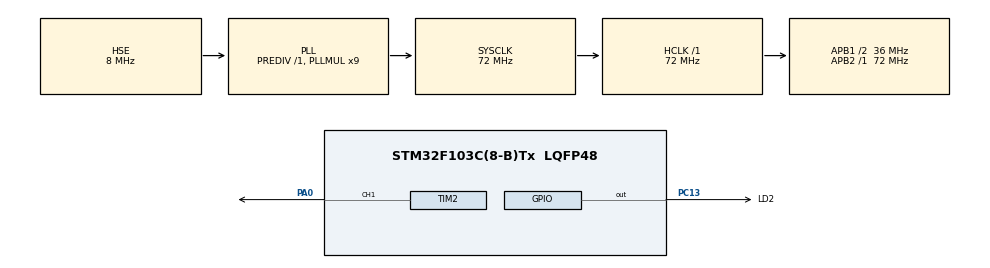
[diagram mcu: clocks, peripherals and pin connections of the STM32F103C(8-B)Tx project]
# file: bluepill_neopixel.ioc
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Dma.Request0=TIM2_CH1
Dma.TIM2_CH1.0.Direction=DMA_MEMORY_TO_PERIPH
Dma.TIM2_CH1.0.Instance=DMA1_Channel5
Dma.TIM2_CH1.0.MemDataAlignment=DMA_MDATAALIGN_HALFWORD
Dma.TIM2_CH1.0.MemInc=DMA_MINC_ENABLE
Dma.TIM2_CH1.0.Mode=DMA_NORMAL
Dma.TIM2_CH1.0.PeriphDataAlignment=DMA_PDATAALIGN_HALFWORD
Dma.TIM2_CH1.0.PeriphInc=DMA_PINC_DISABLE
Dma.TIM2_CH1.0.Priority=DMA_PRIORITY_LOW
Mcu.Family=STM32F1
Mcu.Name=STM32F103C(8-B)Tx
Mcu.Package=LQFP48
NVIC.DMA1_Channel5_IRQn=true\:0\:0\:false\:false\:true\:false\:true\:true
NVIC.PriorityGroup=NVIC_PRIORITYGROUP_4
NVIC.TIM2_IRQn=true\:0\:0\:false\:false\:true\:true\:true\:true
PA0-WKUP.Signal=S_TIM2_CH1_ETR
PA13.Mode=Serial_Wire
PA13.Signal=SYS_JTMS-SWDIO
PA14.Mode=Serial_Wire
PA14.Signal=SYS_JTCK-SWCLK
PC13-TAMPER-RTC.GPIO_Label=LD2
PC13-TAMPER-RTC.GPIO_ModeDefaultOutputPP=GPIO_MODE_OUTPUT_OD
PC13-TAMPER-RTC.GPIO_PuPd=GPIO_PULLUP
PC13-TAMPER-RTC.Signal=GPIO_Output
PC14-OSC32_IN.Mode=LSE-External-Oscillator
PC14-OSC32_IN.Signal=RCC_OSC32_IN
PC15-OSC32_OUT.Mode=LSE-External-Oscillator
PC15-OSC32_OUT.Signal=RCC_OSC32_OUT
PD0-OSC_IN.Mode=HSE-External-Oscillator
PD0-OSC_IN.Signal=RCC_OSC_IN
PD1-OSC_OUT.Mode=HSE-External-Oscillator
PD1-OSC_OUT.Signal=RCC_OSC_OUT
ProjectManager.HeapSize=0x200
ProjectManager.StackSize=0x400
ProjectManager.TargetToolchain=STM32CubeIDE
RCC.AHBFreq_Value=72000000
RCC.APB1CLKDivider=RCC_HCLK_DIV2
RCC.APB1Freq_Value=36000000
RCC.APB1TimFreq_Value=72000000
RCC.APB2Freq_Value=72000000
RCC.APB2TimFreq_Value=72000000
RCC.HCLKFreq_Value=72000000
RCC.PLLMUL=RCC_PLL_MUL9
RCC.PLLSourceVirtual=RCC_PLLSOURCE_HSE
RCC.SYSCLKFreq_VALUE=72000000
RCC.SYSCLKSource=RCC_SYSCLKSOURCE_PLLCLK
RCC.USBFreq_Value=72000000
SH.S_TIM2_CH1_ETR.0=TIM2_CH1,PWM Generation1 CH1
TIM2.Channel-PWM\ Generation1\ CH1=TIM_CHANNEL_1
TIM2.Period=90-1
VP_TIM2_VS_ClockSourceINT.Mode=Internal
board=custom

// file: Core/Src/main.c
/* USER CODE BEGIN Header */
/**
  ******************************************************************************
  * @file           : main.c
  * @brief          : Main program body
  ******************************************************************************
  * @attention
  *
  * Copyright (c) 2024 STMicroelectronics.
  * All rights reserved.
  *
  * This software is licensed under terms that can be found in the LICENSE file
  * in the root directory of this software component.
  * If no LICENSE file comes with this software, it is provided AS-IS.
  *
  ******************************************************************************
  */
/* USER CODE END Header */
#include "main.h"

/* USER CODE BEGIN Includes */
#include "ws2812.h"
/* USER CODE END Includes */

/* USER CODE BEGIN PD */
#define NEOPIXEL_NUM 16
#define NEOPIXEL_BUF_SIZE NEOPIXEL_NUM * WS2812_MSG_LENGTH + 2
#define NPX_TIM_FREQ_HZ 72e6 /* Each clock tick on timer 1 takes around 11.904 nanoseconds */
#define NPX_TIM_CHANNEL TIM_CHANNEL_1
#define NPX_HTIM htim2

/* USER CODE END PD */

TIM_HandleTypeDef htim2;
DMA_HandleTypeDef hdma_tim2_ch1;

void SystemClock_Config(void);
static void MX_GPIO_Init(void);
static void MX_DMA_Init(void);
static void MX_TIM2_Init(void);
void full_led_pulse(WS2812_RGBTypeDef color);
void circular_rainbow(double rotation_time, int rotations);
void circular_rainbow_v2(double rotation_time, int rotations);
void full_led_pulse_hsv(WS2812_HSVTypeDef color);
void soft_start_hsv(WS2812_HSVTypeDef color);

/* USER CODE BEGIN 0 */
WS2812_HandleTypeDef neopixel;
int neopixel_dma_buf_size = NEOPIXEL_BUF_SIZE;
uint16_t neopixel_dma_buf[NEOPIXEL_BUF_SIZE] = {0};

/* USER CODE END 0 */

int main(void)
{

  /* MCU Configuration--------------------------------------------------------*/

  /* Reset of all peripherals, Initializes the Flash interface and the Systick. */
  HAL_Init();

  /* Configure the system clock */
  SystemClock_Config();

  /* Initialize all configured peripherals */
  MX_GPIO_Init();
  MX_DMA_Init();
  MX_TIM2_Init();
  /* USER CODE BEGIN 2 */
  ws2812_init(&neopixel, &NPX_HTIM, NPX_TIM_CHANNEL, NPX_TIM_FREQ_HZ, neopixel_dma_buf, NEOPIXEL_BUF_SIZE, NEOPIXEL_NUM);

  WS2812_HSVTypeDef color = {300.0,1.0,0.15};
  ws2812_reset(&neopixel);

  circular_rainbow(5,1);
  HAL_Delay(2000);

  soft_start_hsv(color);
  /* USER CODE END 2 */

  /* Infinite loop */
  while (1)
  {

  }
}

void SystemClock_Config(void)
{
  RCC_OscInitTypeDef RCC_OscInitStruct = {0};
  RCC_ClkInitTypeDef RCC_ClkInitStruct = {0};

  /** Initializes the RCC Oscillators according to the specified parameters
  * in the RCC_OscInitTypeDef structure.
  */
  RCC_OscInitStruct.OscillatorType = RCC_OSCILLATORTYPE_HSE;
  RCC_OscInitStruct.HSEState = RCC_HSE_ON;
  RCC_OscInitStruct.HSEPredivValue = RCC_HSE_PREDIV_DIV1;
  RCC_OscInitStruct.HSIState = RCC_HSI_ON;
  RCC_OscInitStruct.PLL.PLLState = RCC_PLL_ON;
  RCC_OscInitStruct.PLL.PLLSource = RCC_PLLSOURCE_HSE;
  RCC_OscInitStruct.PLL.PLLMUL = RCC_PLL_MUL9;
  if (HAL_RCC_OscConfig(&RCC_OscInitStruct) != HAL_OK)
  {
    Error_Handler();
  }

  /** Initializes the CPU, AHB and APB buses clocks
  */
  RCC_ClkInitStruct.ClockType = RCC_CLOCKTYPE_HCLK|RCC_CLOCKTYPE_SYSCLK
                              |RCC_CLOCKTYPE_PCLK1|RCC_CLOCKTYPE_PCLK2;
  RCC_ClkInitStruct.SYSCLKSource = RCC_SYSCLKSOURCE_PLLCLK;
  RCC_ClkInitStruct.AHBCLKDivider = RCC_SYSCLK_DIV1;
  RCC_ClkInitStruct.APB1CLKDivider = RCC_HCLK_DIV2;
  RCC_ClkInitStruct.APB2CLKDivider = RCC_HCLK_DIV1;

  if (HAL_RCC_ClockConfig(&RCC_ClkInitStruct, FLASH_LATENCY_2) != HAL_OK)
  {
    Error_Handler();
  }
}

static void MX_TIM2_Init(void)
{

  TIM_ClockConfigTypeDef sClockSourceConfig = {0};
  TIM_MasterConfigTypeDef sMasterConfig = {0};
  TIM_OC_InitTypeDef sConfigOC = {0};

  htim2.Instance = TIM2;
  htim2.Init.Prescaler = 0;
  htim2.Init.CounterMode = TIM_COUNTERMODE_UP;
  htim2.Init.Period = 90-1;
  htim2.Init.ClockDivision = TIM_CLOCKDIVISION_DIV1;
  htim2.Init.AutoReloadPreload = TIM_AUTORELOAD_PRELOAD_DISABLE;
  if (HAL_TIM_Base_Init(&htim2) != HAL_OK)
  {
    Error_Handler();
  }
  sClockSourceConfig.ClockSource = TIM_CLOCKSOURCE_INTERNAL;
  if (HAL_TIM_ConfigClockSource(&htim2, &sClockSourceConfig) != HAL_OK)
  {
    Error_Handler();
  }
  if (HAL_TIM_PWM_Init(&htim2) != HAL_OK)
  {
    Error_Handler();
  }
  sMasterConfig.MasterOutputTrigger = TIM_TRGO_RESET;
  sMasterConfig.MasterSlaveMode = TIM_MASTERSLAVEMODE_DISABLE;
  if (HAL_TIMEx_MasterConfigSynchronization(&htim2, &sMasterConfig) != HAL_OK)
  {
    Error_Handler();
  }
  sConfigOC.OCMode = TIM_OCMODE_PWM1;
  sConfigOC.Pulse = 0;
  sConfigOC.OCPolarity = TIM_OCPOLARITY_HIGH;
  sConfigOC.OCFastMode = TIM_OCFAST_DISABLE;
  if (HAL_TIM_PWM_ConfigChannel(&htim2, &sConfigOC, TIM_CHANNEL_1) != HAL_OK)
  {
    Error_Handler();
  }
  HAL_TIM_MspPostInit(&htim2);

}

static void MX_DMA_Init(void)
{

  /* DMA controller clock enable */
  __HAL_RCC_DMA1_CLK_ENABLE();

  /* DMA interrupt init */
  /* DMA1_Channel5_IRQn interrupt configuration */
  HAL_NVIC_SetPriority(DMA1_Channel5_IRQn, 0, 0);
  HAL_NVIC_EnableIRQ(DMA1_Channel5_IRQn);

}

static void MX_GPIO_Init(void)
{
  GPIO_InitTypeDef GPIO_InitStruct = {0};

  /* GPIO Ports Clock Enable */
  __HAL_RCC_GPIOC_CLK_ENABLE();
  __HAL_RCC_GPIOD_CLK_ENABLE();
  __HAL_RCC_GPIOA_CLK_ENABLE();

  /*Configure GPIO pin Output Level */
  HAL_GPIO_WritePin(LD2_GPIO_Port, LD2_Pin, GPIO_PIN_RESET);

  /*Configure GPIO pin : LD2_Pin */
  GPIO_InitStruct.Pin = LD2_Pin;
  GPIO_InitStruct.Mode = GPIO_MODE_OUTPUT_OD;
  GPIO_InitStruct.Pull = GPIO_PULLUP;
  GPIO_InitStruct.Speed = GPIO_SPEED_FREQ_LOW;
  HAL_GPIO_Init(LD2_GPIO_Port, &GPIO_InitStruct);

}

/* USER CODE BEGIN 4 */
void full_led_pulse(WS2812_RGBTypeDef color){
	int led_buf[16] = {0,1,2,3,4,5,6,7,8,9,10,11,12,13,14,15};
	WS2812_RGBTypeDef color_t = color;
	for(int i=1; i<100; i+=1){
		color_t.r = (uint8_t)(((double)i / 100) * (double)color.r);
		color_t.g = (uint8_t)(((double)i / 100) * (double)color.g);
		color_t.b = (uint8_t)(((double)i / 100) * (double)color.b);

		ws2812_set_color_rgb(&neopixel, led_buf, 16, color_t);
		ws2812_write(&neopixel);
		HAL_Delay(40);
	}
	for(int i=100; i>1; i-=1){
		color_t.r = (uint8_t)(((double)i / 100) * (double)color.r);
		color_t.g = (uint8_t)(((double)i / 100) * (double)color.g);
		color_t.b = (uint8_t)(((double)i / 100) * (double)color.b);

		ws2812_set_color_rgb(&neopixel, led_buf, 16, color_t);
		ws2812_write(&neopixel);
		HAL_Delay(40);
	}
}

void full_led_pulse_hsv(WS2812_HSVTypeDef color){
	int led_buf[16] = {0,1,2,3,4,5,6,7,8,9,10,11,12,13,14,15};
	WS2812_HSVTypeDef color_t = color;
	for(int i=1; i<=100; i+=1){
		color_t.v = (((double)i / 100) * color.v);
		ws2812_set_color_hsv(&neopixel, led_buf, 16, color_t);
		ws2812_write(&neopixel);
		HAL_Delay(40);
	}
	for(int i=100; i>=0; i-=1){
		color_t.v = (((double)i / 100) * color.v);

		ws2812_set_color_hsv(&neopixel, led_buf, 16, color_t);
		ws2812_write(&neopixel);
		HAL_Delay(40);
	}
	HAL_Delay(2000);
	return;
}

void soft_start_hsv(WS2812_HSVTypeDef color){
	int led_buf[16] = {0,1,2,3,4,5,6,7,8,9,10,11,12,13,14,15};
	WS2812_HSVTypeDef color_t = color;
	for(int i=1; i<=100; i+=1){
		color_t.v = (((double)i / 100) * color.v);
		ws2812_set_color_hsv(&neopixel, led_buf, 16, color_t);
		ws2812_write(&neopixel);
		HAL_Delay(40);
	}
	return;
}

void circular_rainbow(double rotation_time, int rotations){
	int led_buf[16] = {0,1,2,3,4,5,6,7,8,9,10,11,12,13,14,15};
	uint32_t delay_period = (uint32_t)(1000 * rotation_time / 360.0);
	WS2812_HSVTypeDef hsv={0,1,1};
	for(int j=0; j<rotations; j++){
		for(int i=1;i<360;i+=1){
			hsv.h = (double)i;
			ws2812_set_color_hsv(&neopixel, led_buf, 16, hsv);
			ws2812_write(&neopixel);
			HAL_Delay(delay_period);
		}
	}
	for(int i=100;i>=0;i--){
		hsv.v -= 0.01;
		ws2812_set_color_hsv(&neopixel, led_buf, 16, hsv);
		ws2812_write(&neopixel);
		HAL_Delay(delay_period);
	}

	return;
}

/* USER CODE END 4 */

void Error_Handler(void)
{
  __disable_irq();
  while (1)
  {
  }
}
